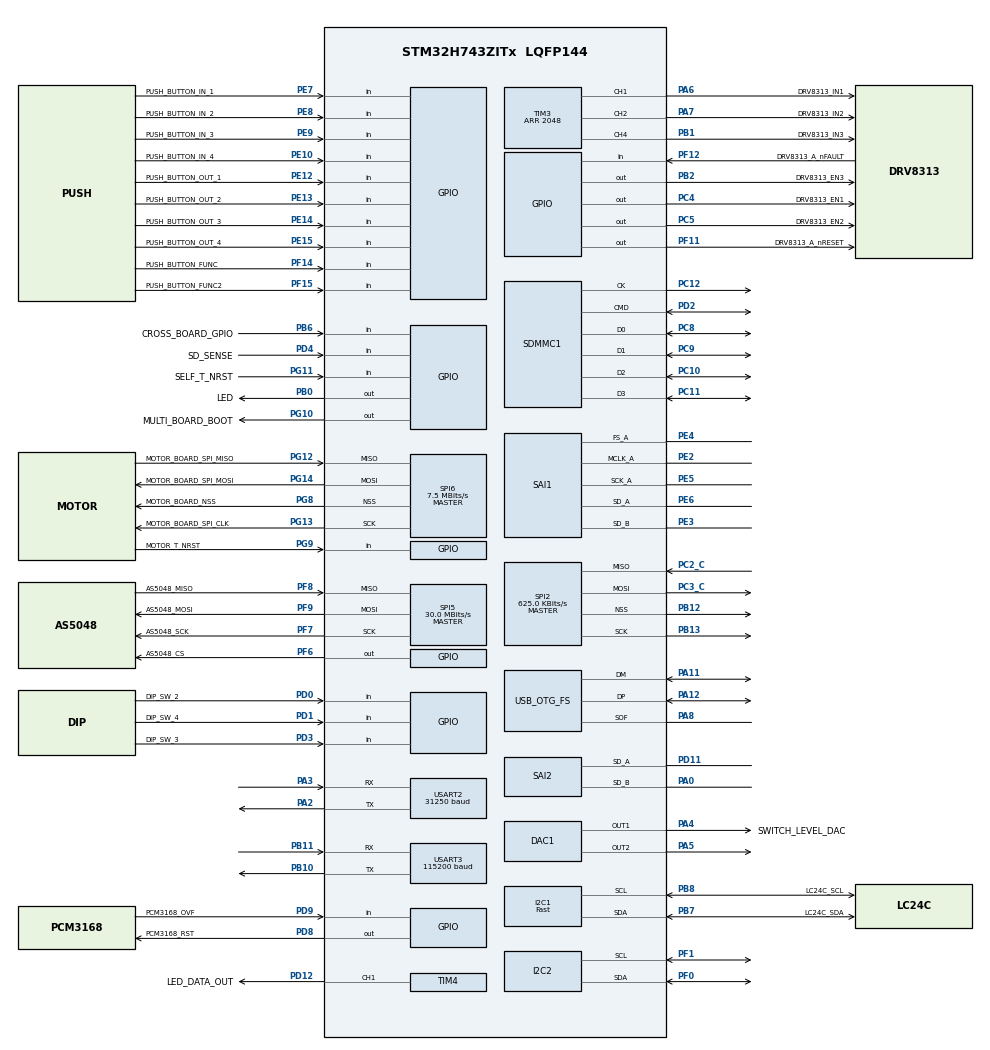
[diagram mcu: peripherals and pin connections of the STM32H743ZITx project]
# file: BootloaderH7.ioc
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DAC1.DAC_Channel-DAC_OUT1=DAC_CHANNEL_1
DAC1.DAC_Channel-DAC_OUT2=DAC_CHANNEL_2
Dma.MEMTOMEM.1.Direction=DMA_MEMORY_TO_MEMORY
Dma.MEMTOMEM.1.EventEnable=DISABLE
Dma.MEMTOMEM.1.FIFOMode=DMA_FIFOMODE_ENABLE
Dma.MEMTOMEM.1.FIFOThreshold=DMA_FIFO_THRESHOLD_FULL
Dma.MEMTOMEM.1.Instance=DMA2_Stream1
Dma.MEMTOMEM.1.MemBurst=DMA_MBURST_SINGLE
Dma.MEMTOMEM.1.MemDataAlignment=DMA_MDATAALIGN_HALFWORD
Dma.MEMTOMEM.1.MemInc=DMA_MINC_ENABLE
Dma.MEMTOMEM.1.Mode=DMA_NORMAL
Dma.MEMTOMEM.1.PeriphBurst=DMA_PBURST_SINGLE
Dma.MEMTOMEM.1.PeriphDataAlignment=DMA_PDATAALIGN_HALFWORD
Dma.MEMTOMEM.1.PeriphInc=DMA_PINC_ENABLE
Dma.MEMTOMEM.1.Polarity=HAL_DMAMUX_REQ_GEN_RISING
Dma.MEMTOMEM.1.Priority=DMA_PRIORITY_LOW
Dma.MEMTOMEM.1.RequestNumber=1
Dma.MEMTOMEM.1.SignalID=NONE
Dma.MEMTOMEM.1.SyncEnable=DISABLE
Dma.MEMTOMEM.1.SyncPolarity=HAL_DMAMUX_SYNC_NO_EVENT
Dma.MEMTOMEM.1.SyncRequestNumber=1
Dma.MEMTOMEM.1.SyncSignalID=NONE
Dma.Request0=TIM4_CH1
Dma.Request1=MEMTOMEM
Dma.Request2=SAI1_A
Dma.Request3=SAI1_B
Dma.Request4=SAI2_A
Dma.Request5=SAI2_B
Dma.SAI1_A.2.Direction=DMA_MEMORY_TO_PERIPH
Dma.SAI1_A.2.EventEnable=DISABLE
Dma.SAI1_A.2.FIFOMode=DMA_FIFOMODE_DISABLE
Dma.SAI1_A.2.Instance=DMA1_Stream0
Dma.SAI1_A.2.MemDataAlignment=DMA_MDATAALIGN_WORD
Dma.SAI1_A.2.MemInc=DMA_MINC_ENABLE
Dma.SAI1_A.2.Mode=DMA_CIRCULAR
Dma.SAI1_A.2.PeriphDataAlignment=DMA_PDATAALIGN_WORD
Dma.SAI1_A.2.PeriphInc=DMA_PINC_DISABLE
Dma.SAI1_A.2.Polarity=HAL_DMAMUX_REQ_GEN_RISING
Dma.SAI1_A.2.Priority=DMA_PRIORITY_MEDIUM
Dma.SAI1_A.2.RequestNumber=1
Dma.SAI1_A.2.SignalID=NONE
Dma.SAI1_A.2.SyncEnable=DISABLE
Dma.SAI1_A.2.SyncPolarity=HAL_DMAMUX_SYNC_NO_EVENT
Dma.SAI1_A.2.SyncRequestNumber=1
Dma.SAI1_A.2.SyncSignalID=NONE
Dma.SAI1_B.3.Direction=DMA_MEMORY_TO_PERIPH
Dma.SAI1_B.3.EventEnable=DISABLE
Dma.SAI1_B.3.FIFOMode=DMA_FIFOMODE_DISABLE
Dma.SAI1_B.3.Instance=DMA1_Stream1
Dma.SAI1_B.3.MemDataAlignment=DMA_MDATAALIGN_WORD
Dma.SAI1_B.3.MemInc=DMA_MINC_ENABLE
Dma.SAI1_B.3.Mode=DMA_CIRCULAR
Dma.SAI1_B.3.PeriphDataAlignment=DMA_PDATAALIGN_WORD
Dma.SAI1_B.3.PeriphInc=DMA_PINC_DISABLE
Dma.SAI1_B.3.Polarity=HAL_DMAMUX_REQ_GEN_RISING
Dma.SAI1_B.3.Priority=DMA_PRIORITY_MEDIUM
Dma.SAI1_B.3.RequestNumber=1
Dma.SAI1_B.3.SignalID=NONE
Dma.SAI1_B.3.SyncEnable=DISABLE
Dma.SAI1_B.3.SyncPolarity=HAL_DMAMUX_SYNC_NO_EVENT
Dma.SAI1_B.3.SyncRequestNumber=1
Dma.SAI1_B.3.SyncSignalID=NONE
Dma.SAI2_A.4.Direction=DMA_PERIPH_TO_MEMORY
Dma.SAI2_A.4.EventEnable=DISABLE
Dma.SAI2_A.4.FIFOMode=DMA_FIFOMODE_DISABLE
Dma.SAI2_A.4.Instance=DMA1_Stream2
Dma.SAI2_A.4.MemDataAlignment=DMA_MDATAALIGN_WORD
Dma.SAI2_A.4.MemInc=DMA_MINC_ENABLE
Dma.SAI2_A.4.Mode=DMA_CIRCULAR
Dma.SAI2_A.4.PeriphDataAlignment=DMA_PDATAALIGN_WORD
Dma.SAI2_A.4.PeriphInc=DMA_PINC_DISABLE
Dma.SAI2_A.4.Polarity=HAL_DMAMUX_REQ_GEN_RISING
Dma.SAI2_A.4.Priority=DMA_PRIORITY_HIGH
Dma.SAI2_A.4.RequestNumber=1
Dma.SAI2_A.4.SignalID=NONE
Dma.SAI2_A.4.SyncEnable=DISABLE
Dma.SAI2_A.4.SyncPolarity=HAL_DMAMUX_SYNC_NO_EVENT
Dma.SAI2_A.4.SyncRequestNumber=1
Dma.SAI2_A.4.SyncSignalID=NONE
Dma.SAI2_B.5.Direction=DMA_PERIPH_TO_MEMORY
Dma.SAI2_B.5.EventEnable=DISABLE
Dma.SAI2_B.5.FIFOMode=DMA_FIFOMODE_DISABLE
Dma.SAI2_B.5.Instance=DMA1_Stream3
Dma.SAI2_B.5.MemDataAlignment=DMA_MDATAALIGN_WORD
Dma.SAI2_B.5.MemInc=DMA_MINC_ENABLE
Dma.SAI2_B.5.Mode=DMA_CIRCULAR
Dma.SAI2_B.5.PeriphDataAlignment=DMA_PDATAALIGN_WORD
Dma.SAI2_B.5.PeriphInc=DMA_PINC_DISABLE
Dma.SAI2_B.5.Polarity=HAL_DMAMUX_REQ_GEN_RISING
Dma.SAI2_B.5.Priority=DMA_PRIORITY_HIGH
Dma.SAI2_B.5.RequestNumber=1
Dma.SAI2_B.5.SignalID=NONE
Dma.SAI2_B.5.SyncEnable=DISABLE
Dma.SAI2_B.5.SyncPolarity=HAL_DMAMUX_SYNC_NO_EVENT
Dma.SAI2_B.5.SyncRequestNumber=1
Dma.SAI2_B.5.SyncSignalID=NONE
Dma.TIM4_CH1.0.Direction=DMA_MEMORY_TO_PERIPH
Dma.TIM4_CH1.0.EventEnable=DISABLE
Dma.TIM4_CH1.0.FIFOMode=DMA_FIFOMODE_DISABLE
Dma.TIM4_CH1.0.Instance=DMA2_Stream0
Dma.TIM4_CH1.0.MemDataAlignment=DMA_MDATAALIGN_HALFWORD
Dma.TIM4_CH1.0.MemInc=DMA_MINC_ENABLE
Dma.TIM4_CH1.0.Mode=DMA_CIRCULAR
Dma.TIM4_CH1.0.PeriphDataAlignment=DMA_PDATAALIGN_HALFWORD
Dma.TIM4_CH1.0.PeriphInc=DMA_PINC_DISABLE
Dma.TIM4_CH1.0.Polarity=HAL_DMAMUX_REQ_GEN_RISING
Dma.TIM4_CH1.0.Priority=DMA_PRIORITY_HIGH
Dma.TIM4_CH1.0.RequestNumber=1
Dma.TIM4_CH1.0.SignalID=NONE
Dma.TIM4_CH1.0.SyncEnable=DISABLE
Dma.TIM4_CH1.0.SyncPolarity=HAL_DMAMUX_SYNC_NO_EVENT
Dma.TIM4_CH1.0.SyncRequestNumber=1
Dma.TIM4_CH1.0.SyncSignalID=NONE
FATFS.BSP.number=1
FATFS.USE_DMA_CODE_SD=1
FATFS._FS_EXFAT=1
FATFS._FS_LOCK=8
FATFS._MAX_SS=4096
FATFS._MIN_SS=512
FATFS._USE_EXPAND=1
FATFS._USE_FASTSEEK=0
FATFS._USE_LFN=1
FATFS._USE_TRIM=1
FATFS0.BSP.STBoard=false
FATFS0.BSP.api=Unknown
FATFS0.BSP.instance=PD4
FATFS0.BSP.ip=GPIO
FATFS0.BSP.mode=Input
FATFS0.BSP.name=Detect_SDIO
FATFS0.BSP.solution=PD4
I2C1.I2C_Speed_Mode=I2C_Fast
I2C1.Timing=0x00B03FDB
I2C2.Timing=0x307075B1
Mcu.Family=STM32H7
Mcu.Name=STM32H743ZITx
Mcu.Package=LQFP144
Mdma.MDMA_Channel0.Request0=SDMMC1_END_DATA
Mdma.MDMA_Channel0.RequestsNb=1
Mdma.MDMA_Channel0.SDMMC1_END_DATA.0.BlockCount=0
Mdma.MDMA_Channel0.SDMMC1_END_DATA.0.BlockDataLength=0
Mdma.MDMA_Channel0.SDMMC1_END_DATA.0.BufferTransferLength=1
Mdma.MDMA_Channel0.SDMMC1_END_DATA.0.CircularMode=MDMA_LINEAR_LIST
Mdma.MDMA_Channel0.SDMMC1_END_DATA.0.DataAlignment=MDMA_DATAALIGN_PACKENABLE
Mdma.MDMA_Channel0.SDMMC1_END_DATA.0.DestBlockAddressOffset=0
Mdma.MDMA_Channel0.SDMMC1_END_DATA.0.DestBurst=MDMA_DEST_BURST_SINGLE
Mdma.MDMA_Channel0.SDMMC1_END_DATA.0.DestDataSize=MDMA_DEST_DATASIZE_BYTE
Mdma.MDMA_Channel0.SDMMC1_END_DATA.0.DestinationInc=MDMA_DEST_INC_BYTE
Mdma.MDMA_Channel0.SDMMC1_END_DATA.0.DstAddress=0
Mdma.MDMA_Channel0.SDMMC1_END_DATA.0.Endianness=MDMA_LITTLE_ENDIANNESS_PRESERVE
Mdma.MDMA_Channel0.SDMMC1_END_DATA.0.Instance=MDMA_Channel0
Mdma.MDMA_Channel0.SDMMC1_END_DATA.0.MaskAddress=0
Mdma.MDMA_Channel0.SDMMC1_END_DATA.0.MaskData=0
Mdma.MDMA_Channel0.SDMMC1_END_DATA.0.Priority=MDMA_PRIORITY_LOW
Mdma.MDMA_Channel0.SDMMC1_END_DATA.0.Rank=First
Mdma.MDMA_Channel0.SDMMC1_END_DATA.0.SourceBlockAddressOffset=0
Mdma.MDMA_Channel0.SDMMC1_END_DATA.0.SourceBurst=MDMA_SOURCE_BURST_SINGLE
Mdma.MDMA_Channel0.SDMMC1_END_DATA.0.SourceDataSize=MDMA_SRC_DATASIZE_BYTE
Mdma.MDMA_Channel0.SDMMC1_END_DATA.0.SourceInc=MDMA_SRC_INC_BYTE
Mdma.MDMA_Channel0.SDMMC1_END_DATA.0.SrcAddress=0
Mdma.MDMA_Channel0.SDMMC1_END_DATA.0.TransferTriggerMode=MDMA_BUFFER_TRANSFER
Mdma.RequestSet0=MDMA_Channel0
Mdma.RequestSetsNb=1
NVIC.DMA1_Stream0_IRQn=true\:0\:0\:false\:false\:true\:false\:true\:true
NVIC.DMA1_Stream1_IRQn=true\:0\:0\:false\:false\:true\:false\:true\:true
NVIC.DMA1_Stream2_IRQn=true\:0\:0\:false\:false\:true\:false\:true\:true
NVIC.DMA1_Stream3_IRQn=true\:0\:0\:false\:false\:true\:false\:true\:true
NVIC.DMA2_Stream0_IRQn=true\:0\:0\:false\:false\:true\:false\:true\:true
NVIC.MDMA_IRQn=true\:0\:0\:false\:false\:true\:false\:true\:true
NVIC.OTG_FS_EP1_IN_IRQn=true\:0\:0\:false\:false\:true\:true\:true\:true
NVIC.OTG_FS_EP1_OUT_IRQn=true\:0\:0\:false\:false\:true\:true\:true\:true
NVIC.OTG_FS_IRQn=true\:0\:0\:false\:false\:true\:false\:true\:true
NVIC.PriorityGroup=NVIC_PRIORITYGROUP_3
NVIC.SAI2_IRQn=true\:0\:0\:false\:false\:true\:true\:true\:true
NVIC.SDMMC1_IRQn=true\:0\:0\:false\:false\:true\:true\:true\:true
NVIC.SPI6_IRQn=true\:0\:0\:false\:false\:true\:true\:true\:true
NVIC.USART3_IRQn=true\:0\:0\:true\:false\:true\:true\:true\:true
PA0.Mode=SAI_B_SyncSlave
PA0.Signal=SAI2_SD_B
PA11.Mode=Device_Only
PA11.Signal=USB_OTG_FS_DM
PA12.Mode=Device_Only
PA12.Signal=USB_OTG_FS_DP
PA13\ (JTMS/SWDIO).Mode=Trace_Asynchronous_SW
PA13\ (JTMS/SWDIO).Signal=DEBUG_JTMS-SWDIO
PA14\ (JTCK/SWCLK).Mode=Trace_Asynchronous_SW
PA14\ (JTCK/SWCLK).Signal=DEBUG_JTCK-SWCLK
PA2.Mode=Asynchronous
PA2.Signal=USART2_TX
PA3.Mode=Asynchronous
PA3.Signal=USART2_RX
PA4.GPIO_Label=SWITCH_LEVEL_DAC
PA4.Signal=COMP_DAC11_group
PA5.Signal=COMP_DAC12_group
PA6.GPIO_Label=DRV8313_IN1
PA6.Signal=S_TIM3_CH1
PA7.GPIO_Label=DRV8313_IN2
PA7.Signal=S_TIM3_CH2
PA8.Mode=Activate_SOF_FS
PA8.Signal=USB_OTG_FS_SOF
PB0.GPIO_Label=LED
PB0.Signal=GPIO_Output
PB1.GPIO_Label=DRV8313_IN3
PB1.Signal=S_TIM3_CH4
PB10.Mode=Asynchronous
PB10.Signal=USART3_TX
PB11.Mode=Asynchronous
PB11.Signal=USART3_RX
PB12.Mode=NSS_Signal_Hard_Output
PB12.Signal=SPI2_NSS
PB13.Mode=Full_Duplex_Master
PB13.Signal=SPI2_SCK
PB2.GPIO_Label=DRV8313_EN3
PB2.Signal=GPIO_Output
PB3\ (JTDO/TRACESWO).Mode=Trace_Asynchronous_SW
PB3\ (JTDO/TRACESWO).Signal=DEBUG_JTDO-SWO
PB6.GPIO_Label=CROSS_BOARD_GPIO
PB6.Signal=GPIO_Input
PB7.GPIO_Label=LC24C_SDA
PB7.GPIO_Pu=GPIO_PULLUP
PB7.Mode=I2C
PB7.Signal=I2C1_SDA
PB8.GPIO_Label=LC24C_SCL
PB8.GPIO_Pu=GPIO_PULLUP
PB8.Mode=I2C
PB8.Signal=I2C1_SCL
PC10.GPIO_PuPd=GPIO_PULLUP
PC10.Mode=SD_4_bits_Wide_bus
PC10.Signal=SDMMC1_D2
PC11.GPIO_PuPd=GPIO_PULLUP
PC11.Mode=SD_4_bits_Wide_bus
PC11.Signal=SDMMC1_D3
PC12.Mode=SD_4_bits_Wide_bus
PC12.Signal=SDMMC1_CK
PC2_C.Mode=Full_Duplex_Master
PC2_C.Signal=SPI2_MISO
PC3_C.Mode=Full_Duplex_Master
PC3_C.Signal=SPI2_MOSI
PC4.GPIO_Label=DRV8313_EN1
PC4.Signal=GPIO_Output
PC5.GPIO_Label=DRV8313_EN2
PC5.Signal=GPIO_Output
PC8.GPIO_PuPd=GPIO_PULLUP
PC8.Mode=SD_4_bits_Wide_bus
PC8.Signal=SDMMC1_D0
PC9.GPIO_PuPd=GPIO_PULLUP
PC9.Mode=SD_4_bits_Wide_bus
PC9.Signal=SDMMC1_D1
PD0.GPIO_Label=DIP_SW_2
PD0.GPIO_PuPd=GPIO_PULLUP
PD0.Signal=GPIO_Input
PD1.GPIO_Label=DIP_SW_4
PD1.GPIO_PuPd=GPIO_PULLUP
PD1.Signal=GPIO_Input
PD11.Mode=SAI_A_SyncSlave
PD11.Signal=SAI2_SD_A
PD12.GPIO_Label=LED_DATA_OUT
PD12.GPIO_PuPd=GPIO_PULLDOWN
PD12.Signal=S_TIM4_CH1
PD2.GPIO_PuPd=GPIO_PULLUP
PD2.Mode=SD_4_bits_Wide_bus
PD2.Signal=SDMMC1_CMD
PD3.GPIO_Label=DIP_SW_3
PD3.Signal=GPIO_Input
PD4.GPIO_Label=SD_SENSE
PD4.GPIO_PuPd=GPIO_PULLUP
PD4.Signal=GPIO_Input
PD8.GPIO_Label=PCM3168_RST
PD8.GPIO_PuPd=GPIO_PULLUP
PD8.PinState=GPIO_PIN_SET
PD8.Signal=GPIO_Output
PD9.GPIO_Label=PCM3168_OVF
PD9.Signal=GPIO_Input
PE10.GPIO_Label=PUSH_BUTTON_IN_4
PE10.Signal=GPIO_Input
PE12.GPIO_Label=PUSH_BUTTON_OUT_1
PE12.Signal=GPIO_Input
PE13.GPIO_Label=PUSH_BUTTON_OUT_2
PE13.Signal=GPIO_Input
PE14.GPIO_Label=PUSH_BUTTON_OUT_3
PE14.Signal=GPIO_Input
PE15.GPIO_Label=PUSH_BUTTON_OUT_4
PE15.Signal=GPIO_Input
PE2.GPIO_Speed=GPIO_SPEED_FREQ_VERY_HIGH
PE2.Mode=SAI_A_MasterWithClock
PE2.Signal=SAI1_MCLK_A
PE3.Mode=SAI_B_SyncSlave
PE3.Signal=SAI1_SD_B
PE4.GPIO_Speed=GPIO_SPEED_FREQ_VERY_HIGH
PE4.Mode=SAI_A_MasterWithClock
PE4.Signal=SAI1_FS_A
PE5.GPIO_Speed=GPIO_SPEED_FREQ_VERY_HIGH
PE5.Mode=SAI_A_MasterWithClock
PE5.Signal=SAI1_SCK_A
PE6.GPIO_Speed=GPIO_SPEED_FREQ_VERY_HIGH
PE6.Mode=SAI_A_MasterWithClock
PE6.Signal=SAI1_SD_A
PE7.GPIO_Label=PUSH_BUTTON_IN_1
PE7.Signal=GPIO_Input
PE8.GPIO_Label=PUSH_BUTTON_IN_2
PE8.Signal=GPIO_Input
PE9.GPIO_Label=PUSH_BUTTON_IN_3
PE9.Signal=GPIO_Input
PF0.GPIO_Pu=GPIO_PULLUP
PF0.Mode=I2C
PF0.Signal=I2C2_SDA
PF1.GPIO_Pu=GPIO_PULLUP
PF1.Mode=I2C
PF1.Signal=I2C2_SCL
PF11.GPIO_Label=DRV8313_A_nRESET
PF11.Signal=GPIO_Output
PF12.GPIO_Label=DRV8313_A_nFAULT
PF12.Signal=GPIO_Input
PF14.GPIO_Label=PUSH_BUTTON_FUNC
PF14.Signal=GPIO_Input
PF15.GPIO_Label=PUSH_BUTTON_FUNC2
PF15.Signal=GPIO_Input
PF6.GPIO_Label=AS5048_CS
PF6.Signal=GPIO_Output
PF7.GPIO_Label=AS5048_SCK
PF7.Mode=Full_Duplex_Master
PF7.Signal=SPI5_SCK
PF8.GPIO_Label=AS5048_MISO
PF8.Mode=Full_Duplex_Master
PF8.Signal=SPI5_MISO
PF9.GPIO_Label=AS5048_MOSI
PF9.Mode=Full_Duplex_Master
PF9.Signal=SPI5_MOSI
PG10.GPIO_Label=MULTI_BOARD_BOOT
PG10.PinState=GPIO_PIN_RESET
PG10.Signal=GPIO_Output
PG11.GPIO_Label=SELF_T_NRST
PG11.Signal=GPIO_Input
PG12.GPIO_Label=MOTOR_BOARD_SPI_MISO
PG12.Mode=Full_Duplex_Master
PG12.Signal=SPI6_MISO
PG13.GPIO_Label=MOTOR_BOARD_SPI_CLK
PG13.Mode=Full_Duplex_Master
PG13.Signal=SPI6_SCK
PG14.GPIO_Label=MOTOR_BOARD_SPI_MOSI
PG14.Mode=Full_Duplex_Master
PG14.Signal=SPI6_MOSI
PG8.GPIO_Label=MOTOR_BOARD_NSS
PG8.Mode=NSS_Signal_Hard_Output
PG8.Signal=SPI6_NSS
PG9.GPIO_Label=MOTOR_T_NRST
PG9.Signal=GPIO_Input
ProjectManager.HeapSize=0x200
ProjectManager.StackSize=0x400
ProjectManager.TargetToolchain=STM32CubeIDE
RCC.ADCCLockSelection=RCC_ADCCLKSOURCE_CLKP
RCC.ADCFreq_Value=64000000
RCC.APB1Freq_Value=120000000
RCC.APB2Freq_Value=120000000
RCC.APB3Freq_Value=120000000
RCC.APB4Freq_Value=120000000
RCC.CortexFreq_Value=480000000
RCC.D1PPRE=RCC_APB3_DIV2
RCC.D2PPRE1=RCC_APB1_DIV2
RCC.D2PPRE2=RCC_APB2_DIV2
RCC.D3PPRE=RCC_APB4_DIV2
RCC.DIVM1=4
RCC.DIVM2=4
RCC.DIVN1=60
RCC.DIVN2=10
RCC.DIVN3=150
RCC.DIVP2=1
RCC.DIVR2=4
RCC.HCLKFreq_Value=240000000
RCC.HPRE=RCC_HCLK_DIV2
RCC.PLL1_VCI_Range-AdvancedSettings=RCC_PLL1VCIRANGE_0
RCC.PLL1_VCO_SEL-AdvancedSettings=RCC_PLL1VCOWIDE
RCC.PLL2FRACN=0
RCC.PLL2_VCI_Range-AdvancedSettings=RCC_PLL2VCIRANGE_3
RCC.PLL2_VCO_SEL-AdvancedSettings=RCC_PLL2VCOWIDE
RCC.PLL3FRACN=0
RCC.PLL3_VCI_Range-AdvancedSettings=RCC_PLL3VCIRANGE_3
RCC.PLLFRACN=0
RCC.PLLSourceVirtual=RCC_PLLSOURCE_HSI
RCC.ProductRev=revV
RCC.RCC_MCO1Source=RCC_MCO1SOURCE_HSI48
RCC.RCC_MCODiv1=RCC_MCODIV_3
RCC.SAI1CLockSelection=RCC_SAI1CLKSOURCE_PLL3
RCC.SAI23CLockSelection=RCC_SAI23CLKSOURCE_PLL3
RCC.SAI4ACLockSelection=RCC_SAI4ACLKSOURCE_PLL3
RCC.SAI4BCLockSelection=RCC_SAI4BCLKSOURCE_PLL3
RCC.SDMMC1CLockSelection=RCC_SDMMCCLKSOURCE_PLL2
RCC.SPI123CLockSelection=RCC_SPI123CLKSOURCE_PLL2
RCC.SYSCLKFreq_VALUE=480000000
RCC.SYSCLKSource=RCC_SYSCLKSOURCE_PLLCLK
RCC.Tim2Mul=2
RCC.USBCLockSelection=RCC_USBCLKSOURCE_HSI48
RCC.USBFreq_Value=48000000
SAI1.AudioFrequency-SAI_A_MasterWithClock=SAI_AUDIO_FREQUENCY_48K
SAI1.AudioMode-SAI_B_SyncSlave=SAI_MODESLAVE_TX
SAI1.BasicDataSize-SAI_A_MasterWithClock=SAI_PROTOCOL_DATASIZE_24BIT
SAI1.BasicDataSize-SAI_B_SyncSlave=SAI_PROTOCOL_DATASIZE_24BIT
SAI1.ErrorAudioFreq-SAI_A_MasterWithClock=1120.7 %
SAI1.InitProtocol-SAI_A_MasterWithClock=Enable
SAI1.InitProtocol-SAI_B_SyncSlave=Enable
SAI1.Instance-SAI_A_MasterWithClock=SAI$Index_Block_A
SAI1.Instance-SAI_B_SyncSlave=SAI$Index_Block_B
SAI1.MClockEnable-SAI_A_MasterWithClock=SAI_MASTERCLOCK_ENABLE
SAI1.NoDivider-SAI_A_MasterWithClock=SAI_MCK_OVERSAMPLING_DISABLE
SAI1.OutputDrive-SAI_A_MasterWithClock=SAI_OUTPUTDRIVE_ENABLE
SAI1.OutputDrive-SAI_B_SyncSlave=SAI_OUTPUTDRIVE_ENABLE
SAI1.RealAudioFreq-SAI_A_MasterWithClock=585.937 KHz
SAI1.SynchroExt=SAI_SYNCEXT_OUTBLOCKA_ENABLE
SAI1.VirtualMode-SAI_A_MasterWithClock=VM_MASTER
SAI1.VirtualMode-SAI_B_SyncSlave=VM_SLAVE
SAI1.VirtualProtocol-SAI_A_BASIC=VM_BASIC_PROTOCOL
SAI1.VirtualProtocol-SAI_B_BASIC=VM_BASIC_PROTOCOL
SAI2.BasicDataSize-SAI_A_SyncSlave=SAI_PROTOCOL_DATASIZE_24BIT
SAI2.BasicDataSize-SAI_B_SyncSlave=SAI_PROTOCOL_DATASIZE_24BIT
SAI2.InitProtocol-SAI_A_SyncSlave=Enable
SAI2.InitProtocol-SAI_B_SyncSlave=Enable
SAI2.Instance-SAI_A_SyncSlave=SAI$Index_Block_A
SAI2.Instance-SAI_B_SyncSlave=SAI$Index_Block_B
SAI2.Synchro_A=SAI_SYNCHRONOUS_EXT_SAI1
SAI2.Synchro_B=SAI_SYNCHRONOUS_EXT_SAI1
SAI2.TriState-SAI_A_SyncSlave=SAI_OUTPUT_RELEASED
SAI2.TriState-SAI_B_SyncSlave=SAI_OUTPUT_RELEASED
SAI2.VirtualMode-SAI_A_SyncSlave=VM_SLAVE
SAI2.VirtualMode-SAI_B_SyncSlave=VM_SLAVE
SAI2.VirtualProtocol-SAI_A_BASIC=VM_BASIC_PROTOCOL
SAI2.VirtualProtocol-SAI_B_BASIC=VM_BASIC_PROTOCOL
SDMMC1.ClockDiv=1
SDMMC1.HardwareFlowControl=SDMMC_HARDWARE_FLOW_CONTROL_ENABLE
SH.COMP_DAC11_group.0=DAC1_OUT1,DAC_OUT1
SH.COMP_DAC12_group.0=DAC1_OUT2,DAC_OUT2
SH.S_TIM3_CH1.0=TIM3_CH1,PWM Generation1 CH1
SH.S_TIM3_CH2.0=TIM3_CH2,PWM Generation2 CH2
SH.S_TIM3_CH4.0=TIM3_CH4,PWM Generation4 CH4
SH.S_TIM4_CH1.0=TIM4_CH1,PWM Generation1 CH1
SPI2.BaudRatePrescaler=SPI_BAUDRATEPRESCALER_256
SPI2.CLKPolarity=SPI_POLARITY_LOW
SPI2.CalculateBaudRate=625.0 KBits/s
SPI2.DataSize=SPI_DATASIZE_16BIT
SPI2.Direction=SPI_DIRECTION_2LINES
SPI2.Mode=SPI_MODE_MASTER
SPI2.NSSPolarity=SPI_NSS_POLARITY_LOW
SPI2.TIMode=SPI_TIMODE_DISABLE
SPI2.VirtualNSS=VM_NSSHARD
SPI2.VirtualType=VM_MASTER
SPI5.BaudRatePrescaler=SPI_BAUDRATEPRESCALER_4
SPI5.CLKPhase=SPI_PHASE_2EDGE
SPI5.CalculateBaudRate=30.0 MBits/s
SPI5.DataSize=SPI_DATASIZE_16BIT
SPI5.Direction=SPI_DIRECTION_2LINES
SPI5.Mode=SPI_MODE_MASTER
SPI5.NSSPMode=SPI_NSS_PULSE_ENABLE
SPI5.VirtualType=VM_MASTER
SPI6.BaudRatePrescaler=SPI_BAUDRATEPRESCALER_16
SPI6.CalculateBaudRate=7.5 MBits/s
SPI6.DataSize=SPI_DATASIZE_16BIT
SPI6.Direction=SPI_DIRECTION_2LINES
SPI6.Mode=SPI_MODE_MASTER
SPI6.VirtualNSS=VM_NSSHARD
SPI6.VirtualType=VM_MASTER
TIM2.Period=10240
TIM2.Prescaler=16
TIM3.Channel-PWM\ Generation1\ CH1=TIM_CHANNEL_1
TIM3.Channel-PWM\ Generation2\ CH2=TIM_CHANNEL_2
TIM3.Channel-PWM\ Generation4\ CH4=TIM_CHANNEL_4
TIM3.CounterMode=TIM_COUNTERMODE_CENTERALIGNED1
TIM3.Period=2048
TIM3.Pulse-PWM\ Generation1\ CH1=1024
TIM3.Pulse-PWM\ Generation2\ CH2=1024
TIM3.Pulse-PWM\ Generation4\ CH4=1024
TIM4.Channel-PWM\ Generation1\ CH1=TIM_CHANNEL_1
TIM4.OCFastMode_PWM-PWM\ Generation1\ CH1=TIM_OCFAST_ENABLE
TIM4.Period=350
TIM4.Pulse-PWM\ Generation1\ CH1=60
USART2.BaudRate=31250
USART2.VirtualMode-Asynchronous=VM_ASYNC
USART3.AutoBaudRateEnableParam=UART_ADVFEATURE_AUTOBAUDRATE_DISABLE
USART3.BaudRate=115200
USART3.OneBitSampling=UART_ONE_BIT_SAMPLE_DISABLE
USART3.OverSampling=UART_OVERSAMPLING_16
USART3.RXFIFOThreshold=RXFIFO_THRESHOLD_1EIGHTHFULL
USART3.TXFIFOThreshold=TXFIFO_THRESHOLD_1EIGHTHFULL
USART3.VirtualMode-Asynchronous=VM_ASYNC
USB_DEVICE.CLASS_NAME_FS=CDC
USB_DEVICE.MANUFACTURER_STRING-CDC_FS=subMatrix
USB_DEVICE.PRODUCT_STRING_CDC_FS=subMatrix BeetTweek
USB_DEVICE.VirtualMode-CDC_FS=Cdc
USB_DEVICE.VirtualModeFS=Cdc_FS
USB_OTG_FS.Sof_enable=ENABLE
USB_OTG_FS.VirtualMode=Device_Only
VP_FATFS_VS_SDIO.Mode=SDIO
VP_RNG_VS_RNG.Mode=RNG_Activate
VP_SAI1_VP_$IpInstance_SAIA_SAI_BASIC.Mode=SAI_A_BASIC
VP_SAI1_VP_$IpInstance_SAIB_SAI_BASIC.Mode=SAI_B_BASIC
VP_SAI1_VP_$IpInstance_SYNCHRO_EXTERNAL.Mode=SynchroExternal
VP_SAI2_VP_$IpInstance_SAIA_SAI_BASIC.Mode=SAI_A_BASIC
VP_SAI2_VP_$IpInstance_SAIB_SAI_BASIC.Mode=SAI_B_BASIC
VP_TIM2_VS_ClockSourceINT.Mode=Internal
VP_TIM4_VS_ClockSourceINT.Mode=Internal
VP_TIM5_VS_ClockSourceINT.Mode=Internal
VP_USB_DEVICE_VS_USB_DEVICE_CDC_FS.Mode=CDC_FS
board=custom

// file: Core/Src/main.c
/* USER CODE BEGIN Header */
/**
  ******************************************************************************
  * @file           : main.c
  * @brief          : Main program body
  ******************************************************************************
  * @attention
  *
  * Copyright (c) 2022 STMicroelectronics.
  * All rights reserved.
  *
  * This software is licensed under terms that can be found in the LICENSE file
  * in the root directory of this software component.
  * If no LICENSE file comes with this software, it is provided AS-IS.
  *
  ******************************************************************************
  */
/* USER CODE END Header */
#include "main.h"
#include "dac.h"
#include "dma.h"
#include "fatfs.h"
#include "i2c.h"
#include "mdma.h"
#include "rng.h"
#include "sai.h"
#include "sdmmc.h"
#include "spi.h"
#include "tim.h"
#include "usart.h"
#include "usb_device.h"
#include "gpio.h"

/* USER CODE BEGIN Includes */
#include <stdio.h>
#include "ProgressIndication.h"
#include "verificationProgram.h"
/* USER CODE END Includes */

/* USER CODE BEGIN PTD */
#define FIRMWARE_UPDATE_FILENAME "FIRMWARE.bin"
#define APPLICATION_ADDRESS (0x08040000)
#define APPLICATION_SECTOR (2)
#define APPLICATION_NSECTORS (14)
/* USER CODE END PTD */

/* USER CODE BEGIN PV */
char errorCode[256] = "NOT CALLED FROM USERCODE";
volatile int panelReversed = 0;

/* USER CODE END PV */

void SystemClock_Config(void);
void PeriphCommonClock_Config(void);

/* USER CODE BEGIN 0 */
static void goto_application( void )
{
	FATFS_UnLinkDriver(SDPath);
	HAL_SD_DeInit(&hsd1);

	printf("Jumping To Application..\r\n");

	void (*app_reset_handler) (void) = (void*) (*(volatile uint32_t *) (APPLICATION_ADDRESS + 4));

	//__set_MSP(*(uint32_t *)APPLICATION_ADDRESS);

	HAL_GPIO_WritePin(GPIOB, GPIO_PIN_0, GPIO_PIN_RESET);

	app_reset_handler();

}

int DoFirmwareUpdateFromSDCard()
{
	printf("Checking SD Card For Firmware Update..\r\n");
	UpdateProgressPercent(0, 1.0f, 1.0f, 0.0f);

	//Get SD and FatFs running.
	if(f_mount(&SDFatFS, (TCHAR const*)SDPath, 0) != FR_OK)
	{
		Error_Handler();
	}

	FIL FIRMWARE_FILE;
	FRESULT fr;
	FILINFO fno;
	int exists;
	fr = f_stat(FIRMWARE_UPDATE_FILENAME, &fno);
	switch (fr) {
		case FR_OK: exists = 1; break;
		default: exists = 0;
	}

	if(!exists)
		return 0;

	FRESULT res = f_open(&FIRMWARE_FILE, FIRMWARE_UPDATE_FILENAME, FA_READ);
	if(res != FR_OK)
		return 0;

	HAL_FLASH_Unlock();

	int retries = 3;
	int dataVerified = 1;
	do {
		dataVerified = 1;
		printf("	Erasing Application Flash (Bank1)...\r\n");
		FLASH_EraseInitTypeDef EraseInitStruct;
		uint32_t SectorError;

		EraseInitStruct.TypeErase     = FLASH_TYPEERASE_SECTORS;
		EraseInitStruct.Sector        = APPLICATION_SECTOR;
		EraseInitStruct.Banks         = FLASH_BANK_1;
		EraseInitStruct.NbSectors     = APPLICATION_NSECTORS - 8;
		EraseInitStruct.VoltageRange  = FLASH_VOLTAGE_RANGE_3;

		HAL_StatusTypeDef ret = HAL_FLASHEx_Erase( &EraseInitStruct, &SectorError );
		if((ret != HAL_OK) || (SectorError != 0xFFFFFFFF))
			Error_Handler();

		UpdateProgressPercent(10,  1.0f, 1.0f, 0.0f);

		printf("	Erasing Application Flash (Bank2)...\r\n");
		EraseInitStruct.TypeErase     = FLASH_TYPEERASE_SECTORS;
		EraseInitStruct.Sector        = 0;
		EraseInitStruct.Banks         = FLASH_BANK_2;
		EraseInitStruct.NbSectors     = 8;                    //erase all sectors on bank2
		EraseInitStruct.VoltageRange  = FLASH_VOLTAGE_RANGE_3;

		ret = HAL_FLASHEx_Erase( &EraseInitStruct, &SectorError );
		if((ret != HAL_OK) || (SectorError != 0xFFFFFFFF))
			Error_Handler();

		UpdateProgressPercent(20, 1.0f, 1.0f, 0.0f);

		printf("	Reading and Programming...\r\n");

		fr = f_lseek(&FIRMWARE_FILE, 0);
		if(fr != FR_OK)
			Error_Handler();

		int flashAddressByteOffset = 0;
		int progress = 0;
		while(f_eof(&FIRMWARE_FILE) == 0)
		{
			//read 256bits (H7 flashword size)
			uint8_t data[4*8];
			UINT bytesRead;
			fr = f_read(&FIRMWARE_FILE, data, 4*8, &bytesRead);
			if(fr != FR_OK)
				Error_Handler();

			//write 256bits

			FLASH->CR1 |= FLASH_VOLTAGE_RANGE_3;
			FLASH->CR2 |= FLASH_VOLTAGE_RANGE_3;
			ret = HAL_FLASH_Program(FLASH_TYPEPROGRAM_FLASHWORD, APPLICATION_ADDRESS+flashAddressByteOffset, (uint32_t)(&data[0]));
			if(ret != HAL_OK)
				Error_Handler();

			flashAddressByteOffset+=32;
			progress++;
			if(progress >= 60)
				progress = 60;

			UpdateProgressPercent(progress, 1.0f, 1.0f, 0.0f);
		}

		printf("	Verifying...\r\n");
		UpdateProgressPercent(80, 1.0f, 1.0f, 0.0f);

		fr = f_lseek(&FIRMWARE_FILE, 0);
		if(fr != FR_OK)
			Error_Handler();

		uint32_t flashAddress = APPLICATION_ADDRESS;
		while(f_eof(&FIRMWARE_FILE) == 0)
		{
			//read 1byte from file
			uint8_t data;
			UINT bytesRead;
			fr = f_read(&FIRMWARE_FILE, &data, 1, &bytesRead);
			if(fr != FR_OK)
				Error_Handler();

			uint8_t flashVal = *(uint32_t*)flashAddress;

			if(data != flashVal)
			{
				dataVerified = 0;
				break;
			}

			flashAddress++;
		}

		if(dataVerified)
		{
			printf("	Flash Verified.\r\n");
		}
		else
		{
			printf("	Flash Verification Error, retries left: %d\r\n", retries-1);

		}

		retries--;
	}while(dataVerified == 0 && retries > 0);

	HAL_FLASH_Lock();

	if(dataVerified)
	{
		printf("	Flash Programmed.\r\n");

		fr = f_close(&FIRMWARE_FILE);
		if(fr != FR_OK)
			Error_Handler();

		printf("	Removing Firmware File From SD..\r\n");

		fr = f_unlink("FIRMWARE.bin");
		if(fr != FR_OK)
			Error_Handler();

		//unmount
		f_mount(0, (TCHAR const*)SDPath, 0);
	}
	else
	{
		printf("SD Programming Attempts Failed.\r\n");
		Error_Handler();
	}

	return 1;
}

/* USER CODE END 0 */

int main(void)
{

  /* MCU Configuration--------------------------------------------------------*/

  /* Reset of all peripherals, Initializes the Flash interface and the Systick. */
  HAL_Init();

  /* USER CODE BEGIN Init */

  //goto_application( );

  /* USER CODE END Init */

  /* Configure the system clock */
  SystemClock_Config();

  /* Configure the peripherals common clocks */
  PeriphCommonClock_Config();

  /* Initialize all configured peripherals */
  MX_GPIO_Init();
  MX_DMA_Init();
  MX_MDMA_Init();
  MX_DAC1_Init();
  MX_TIM4_Init();
  MX_USART3_UART_Init();
  MX_TIM2_Init();
  MX_RNG_Init();
  MX_I2C1_Init();
  MX_TIM5_Init();
  MX_SAI1_Init();
  MX_SDMMC1_SD_Init();
  MX_SPI6_Init();
  MX_I2C2_Init();
  MX_USART2_UART_Init();
  MX_SPI2_Init();
  MX_SAI2_Init();
  MX_FATFS_Init();
  MX_TIM3_Init();
  MX_SPI5_Init();
  MX_USB_DEVICE_Init();
  /* USER CODE BEGIN 2 */
#ifdef BOARD_VERIFICATION_MODE
	//do board verification routine. (blink light 1 second intervals and turn on motor pins for oscope.) manufacturing.
	BoardVerificationInit();
	while(1)
	{
	  BoardVerificationLoopUpdate();
	}
#endif

  printf("Starting Bootloader..\r\n");

  InitProgress();

	int sdResult = DoFirmwareUpdateFromSDCard();
	if(sdResult == 0)
	{
	  printf("No SD Firmware Update.\r\n");
	  for(int i = 0; i < 100; i++)
	  {
		  HAL_Delay(2);
		  UpdateProgressPercent(i, 0.0f, 0.0f, 1.0f);
	  }
	}
	else
	{
		UpdateProgressPercent(100, 1.0f, 0.5f, 0.25f);
	}

	  DeInitProgess();

  goto_application();
  /* USER CODE END 2 */

  /* Infinite loop */
  while (1)
  {

  }
}

void SystemClock_Config(void)
{
  RCC_OscInitTypeDef RCC_OscInitStruct = {0};
  RCC_ClkInitTypeDef RCC_ClkInitStruct = {0};

  /** Supply configuration update enable
  */
  HAL_PWREx_ConfigSupply(PWR_LDO_SUPPLY);

  /** Configure the main internal regulator output voltage
  */
  __HAL_PWR_VOLTAGESCALING_CONFIG(PWR_REGULATOR_VOLTAGE_SCALE0);

  while(!__HAL_PWR_GET_FLAG(PWR_FLAG_VOSRDY)) {}

  /** Initializes the RCC Oscillators according to the specified parameters
  * in the RCC_OscInitTypeDef structure.
  */
  RCC_OscInitStruct.OscillatorType = RCC_OSCILLATORTYPE_HSI48|RCC_OSCILLATORTYPE_HSI;
  RCC_OscInitStruct.HSIState = RCC_HSI_DIV1;
  RCC_OscInitStruct.HSICalibrationValue = RCC_HSICALIBRATION_DEFAULT;
  RCC_OscInitStruct.HSI48State = RCC_HSI48_ON;
  RCC_OscInitStruct.PLL.PLLState = RCC_PLL_ON;
  RCC_OscInitStruct.PLL.PLLSource = RCC_PLLSOURCE_HSI;
  RCC_OscInitStruct.PLL.PLLM = 4;
  RCC_OscInitStruct.PLL.PLLN = 60;
  RCC_OscInitStruct.PLL.PLLP = 2;
  RCC_OscInitStruct.PLL.PLLQ = 2;
  RCC_OscInitStruct.PLL.PLLR = 2;
  RCC_OscInitStruct.PLL.PLLRGE = RCC_PLL1VCIRANGE_3;
  RCC_OscInitStruct.PLL.PLLVCOSEL = RCC_PLL1VCOWIDE;
  RCC_OscInitStruct.PLL.PLLFRACN = 0;
  if (HAL_RCC_OscConfig(&RCC_OscInitStruct) != HAL_OK)
  {
    Error_Handler();
  }

  /** Initializes the CPU, AHB and APB buses clocks
  */
  RCC_ClkInitStruct.ClockType = RCC_CLOCKTYPE_HCLK|RCC_CLOCKTYPE_SYSCLK
                              |RCC_CLOCKTYPE_PCLK1|RCC_CLOCKTYPE_PCLK2
                              |RCC_CLOCKTYPE_D3PCLK1|RCC_CLOCKTYPE_D1PCLK1;
  RCC_ClkInitStruct.SYSCLKSource = RCC_SYSCLKSOURCE_PLLCLK;
  RCC_ClkInitStruct.SYSCLKDivider = RCC_SYSCLK_DIV1;
  RCC_ClkInitStruct.AHBCLKDivider = RCC_HCLK_DIV2;
  RCC_ClkInitStruct.APB3CLKDivider = RCC_APB3_DIV2;
  RCC_ClkInitStruct.APB1CLKDivider = RCC_APB1_DIV2;
  RCC_ClkInitStruct.APB2CLKDivider = RCC_APB2_DIV2;
  RCC_ClkInitStruct.APB4CLKDivider = RCC_APB4_DIV2;

  if (HAL_RCC_ClockConfig(&RCC_ClkInitStruct, FLASH_LATENCY_4) != HAL_OK)
  {
    Error_Handler();
  }
}

void PeriphCommonClock_Config(void)
{
  RCC_PeriphCLKInitTypeDef PeriphClkInitStruct = {0};

  /** Initializes the peripherals clock
  */
  PeriphClkInitStruct.PeriphClockSelection = RCC_PERIPHCLK_SDMMC|RCC_PERIPHCLK_SAI1
                              |RCC_PERIPHCLK_SAI2|RCC_PERIPHCLK_SPI2;
  PeriphClkInitStruct.PLL2.PLL2M = 4;
  PeriphClkInitStruct.PLL2.PLL2N = 10;
  PeriphClkInitStruct.PLL2.PLL2P = 1;
  PeriphClkInitStruct.PLL2.PLL2Q = 2;
  PeriphClkInitStruct.PLL2.PLL2R = 4;
  PeriphClkInitStruct.PLL2.PLL2RGE = RCC_PLL2VCIRANGE_3;
  PeriphClkInitStruct.PLL2.PLL2VCOSEL = RCC_PLL2VCOMEDIUM;
  PeriphClkInitStruct.PLL2.PLL2FRACN = 0;
  PeriphClkInitStruct.PLL3.PLL3M = 32;
  PeriphClkInitStruct.PLL3.PLL3N = 150;
  PeriphClkInitStruct.PLL3.PLL3P = 2;
  PeriphClkInitStruct.PLL3.PLL3Q = 2;
  PeriphClkInitStruct.PLL3.PLL3R = 2;
  PeriphClkInitStruct.PLL3.PLL3RGE = RCC_PLL3VCIRANGE_1;
  PeriphClkInitStruct.PLL3.PLL3VCOSEL = RCC_PLL3VCOWIDE;
  PeriphClkInitStruct.PLL3.PLL3FRACN = 0;
  PeriphClkInitStruct.SdmmcClockSelection = RCC_SDMMCCLKSOURCE_PLL2;
  PeriphClkInitStruct.Sai1ClockSelection = RCC_SAI1CLKSOURCE_PLL3;
  PeriphClkInitStruct.Sai23ClockSelection = RCC_SAI23CLKSOURCE_PLL3;
  PeriphClkInitStruct.Spi123ClockSelection = RCC_SPI123CLKSOURCE_PLL2;
  if (HAL_RCCEx_PeriphCLKConfig(&PeriphClkInitStruct) != HAL_OK)
  {
    Error_Handler();
  }
}

/* USER CODE BEGIN 4 */

int __io_putchar(int ch)
{
	HAL_StatusTypeDef status =  HAL_UART_Transmit(&huart3, (uint8_t*)&ch, 1, HAL_MAX_DELAY);
	//CDC_Transmit_FS((uint8_t*)&ch, 1);
	return ch;
}

/* USER CODE END 4 */

void Error_Handler(void)
{
  __disable_irq();
  while (1)
  {
  }
}
